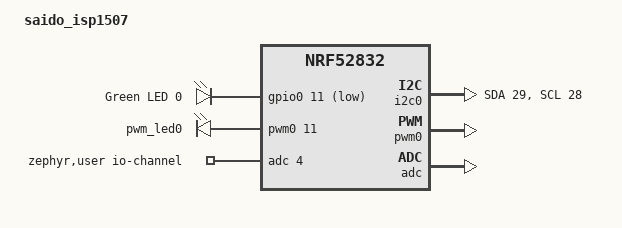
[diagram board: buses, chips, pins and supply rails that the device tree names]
// Copyright (c) 2022 Nordic Semiconductor ASA
// SPDX-License-Identifier: Apache-2.0

/dts-v1/;
#include <nordic/nrf52832_ciaa.dtsi>

/ {
	model = "saido_isp1507";
	compatible = "h-saido,saido-isp1507";

	chosen {
		zephyr,sram = &sram0;
		zephyr,flash = &flash0;
		zephyr,code-partition = &slot0_partition;
	};

	leds {
		compatible = "gpio-leds";
		led0: led_0 {
			gpios = <&gpio0 11 GPIO_ACTIVE_LOW>;
			label = "Green LED 0";
		};
	};

	pwmleds {
		compatible = "pwm-leds";
		pwm_led0: pwm_led_0 {
			pwms = <&pwm0 11>;
		};
	};


	/* These aliases are provided for compatibility with samples */
	aliases {
		led0 = &led0;
		pwm-led0 = &pwm_led0;
		bootloader-led0 = &led0;
	};

	zephyr,user {
		io-channels = <&adc 4>;
	 };
};

&gpio0 {
	status = "okay";
};

i2c: &i2c0 {
	compatible = "nordic,nrf-twi";
	status = "okay";
	sda-pin = <29>;
	scl-pin = <28>;
};

&pwm0 {
	status = "okay";
	ch0-pin = <11>;
	ch0-inverted;
};

&adc {
	status = "okay";
};

&flash0 {
	partitions {
		compatible = "fixed-partitions";
		#address-cells = <1>;
		#size-cells = <1>;

		boot_partition: partition@0 {
			label = "mcuboot";
			reg = <0x0 0xc000>;
		};
		slot0_partition: partition@c000 {
			label = "image-0";
			reg = <0xc000 0x32000>;
		};
		slot1_partition: partition@3e000 {
			label = "image-1";
			reg = <0x3e000 0x32000>;
		};
		scratch_partition: partition@70000 {
			label = "image-scratch";
			reg = <0x70000 0xa000>;
		};
		storage_partition: partition@7a000 {
			label = "storage";
			reg = <0x7a000 0x6000>;
		};
	};
};

